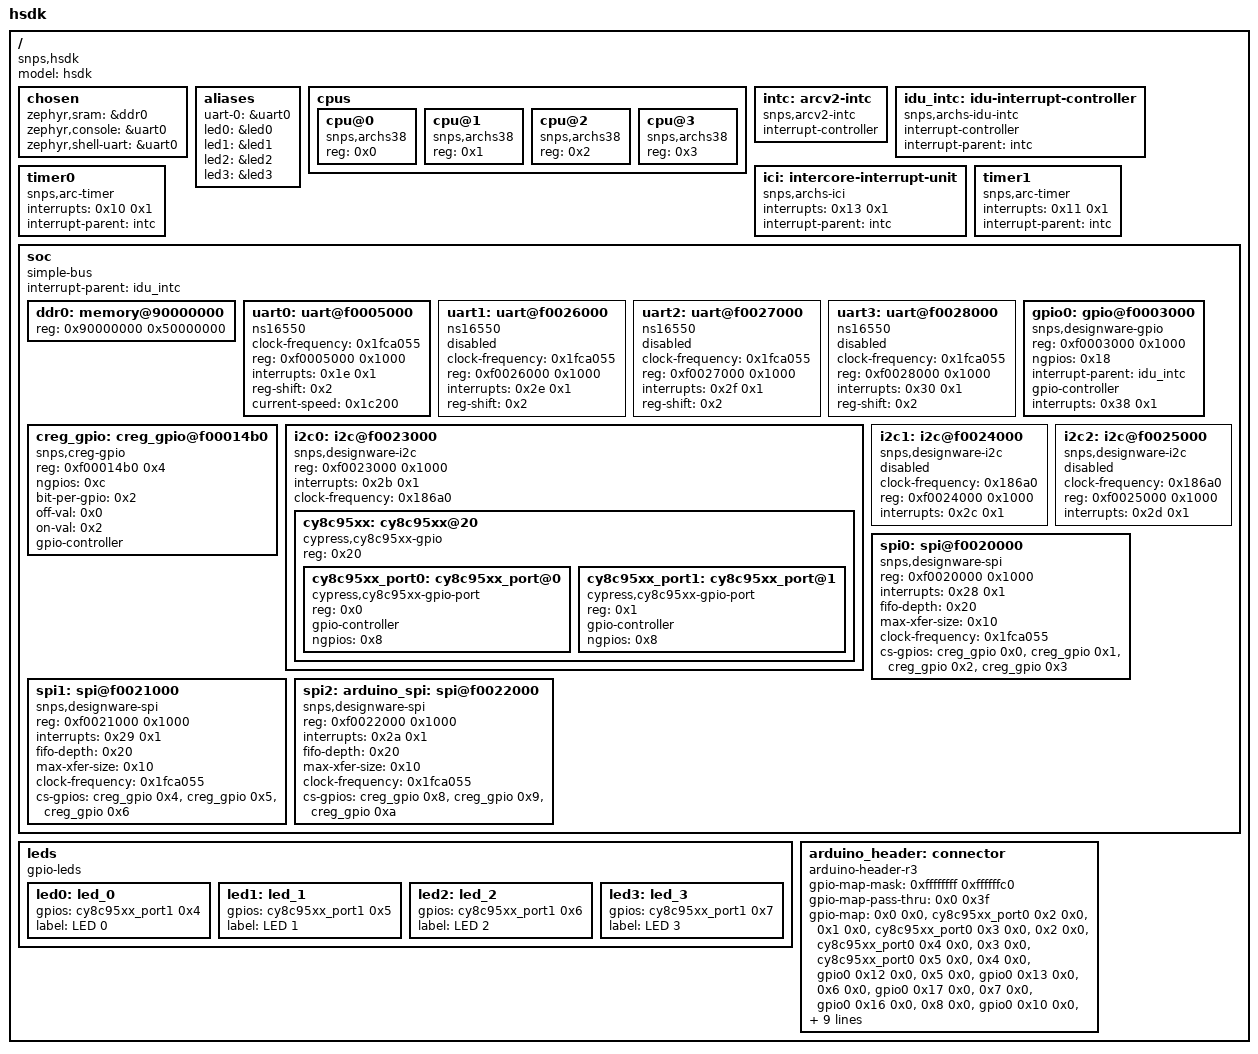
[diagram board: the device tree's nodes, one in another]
/dts-v1/;

/* node '/' defined in zephyr/dts/common/skeleton.dtsi:9 */
/ {
	#address-cells = < 0x1 >; /* in zephyr/dts/common/skeleton.dtsi:10 */
	#size-cells = < 0x1 >;    /* in zephyr/dts/common/skeleton.dtsi:11 */
	model = "hsdk";           /* in zephyr/boards/snps/hsdk/hsdk.dts:12 */
	compatible = "snps,hsdk"; /* in zephyr/boards/snps/hsdk/hsdk.dts:13 */

	/* node '/chosen' defined in zephyr/dts/common/skeleton.dtsi:13 */
	chosen {
		zephyr,sram = &ddr0;        /* in zephyr/boards/snps/hsdk/hsdk.dtsi:46 */
		zephyr,console = &uart0;    /* in zephyr/boards/snps/hsdk/hsdk.dtsi:47 */
		zephyr,shell-uart = &uart0; /* in zephyr/boards/snps/hsdk/hsdk.dtsi:48 */
	};

	/* node '/aliases' defined in zephyr/dts/common/skeleton.dtsi:15 */
	aliases {
		uart-0 = &uart0; /* in zephyr/boards/snps/hsdk/hsdk.dtsi:14 */
		led0 = &led0;    /* in zephyr/boards/snps/hsdk/hsdk.dtsi:15 */
		led1 = &led1;    /* in zephyr/boards/snps/hsdk/hsdk.dtsi:16 */
		led2 = &led2;    /* in zephyr/boards/snps/hsdk/hsdk.dtsi:17 */
		led3 = &led3;    /* in zephyr/boards/snps/hsdk/hsdk.dtsi:18 */
	};

	/* node '/cpus' defined in zephyr/dts/arc/synopsys/arc_hsdk.dtsi:13 */
	cpus {
		#address-cells = < 0x1 >; /* in zephyr/dts/arc/synopsys/arc_hsdk.dtsi:14 */
		#size-cells = < 0x0 >;    /* in zephyr/dts/arc/synopsys/arc_hsdk.dtsi:15 */

		/* node '/cpus/cpu@0' defined in zephyr/dts/arc/synopsys/arc_hsdk.dtsi:17 */
		cpu@0 {
			device_type = "cpu";         /* in zephyr/dts/arc/synopsys/arc_hsdk.dtsi:18 */
			compatible = "snps,archs38"; /* in zephyr/dts/arc/synopsys/arc_hsdk.dtsi:19 */
			reg = < 0x0 >;               /* in zephyr/dts/arc/synopsys/arc_hsdk.dtsi:20 */
		};

		/* node '/cpus/cpu@1' defined in zephyr/dts/arc/synopsys/arc_hsdk.dtsi:23 */
		cpu@1 {
			device_type = "cpu";         /* in zephyr/dts/arc/synopsys/arc_hsdk.dtsi:24 */
			compatible = "snps,archs38"; /* in zephyr/dts/arc/synopsys/arc_hsdk.dtsi:25 */
			reg = < 0x1 >;               /* in zephyr/dts/arc/synopsys/arc_hsdk.dtsi:26 */
		};

		/* node '/cpus/cpu@2' defined in zephyr/dts/arc/synopsys/arc_hsdk.dtsi:29 */
		cpu@2 {
			device_type = "cpu";         /* in zephyr/dts/arc/synopsys/arc_hsdk.dtsi:30 */
			compatible = "snps,archs38"; /* in zephyr/dts/arc/synopsys/arc_hsdk.dtsi:31 */
			reg = < 0x2 >;               /* in zephyr/dts/arc/synopsys/arc_hsdk.dtsi:32 */
		};

		/* node '/cpus/cpu@3' defined in zephyr/dts/arc/synopsys/arc_hsdk.dtsi:35 */
		cpu@3 {
			device_type = "cpu";         /* in zephyr/dts/arc/synopsys/arc_hsdk.dtsi:36 */
			compatible = "snps,archs38"; /* in zephyr/dts/arc/synopsys/arc_hsdk.dtsi:37 */
			reg = < 0x3 >;               /* in zephyr/dts/arc/synopsys/arc_hsdk.dtsi:38 */
		};
	};

	/* node '/arcv2-intc' defined in zephyr/dts/arc/synopsys/arc_hsdk.dtsi:42 */
	intc: arcv2-intc {
		compatible = "snps,arcv2-intc"; /* in zephyr/dts/arc/synopsys/arc_hsdk.dtsi:43 */
		interrupt-controller;           /* in zephyr/dts/arc/synopsys/arc_hsdk.dtsi:44 */
		#interrupt-cells = < 0x2 >;     /* in zephyr/dts/arc/synopsys/arc_hsdk.dtsi:45 */
		phandle = < 0x1 >;              /* in zephyr/dts/arc/synopsys/arc_hsdk.dtsi:52 */
	};

	/* node '/idu-interrupt-controller' defined in zephyr/dts/arc/synopsys/arc_hsdk.dtsi:48 */
	idu_intc: idu-interrupt-controller {
		compatible = "snps,archs-idu-intc"; /* in zephyr/dts/arc/synopsys/arc_hsdk.dtsi:49 */
		interrupt-controller;               /* in zephyr/dts/arc/synopsys/arc_hsdk.dtsi:50 */
		#interrupt-cells = < 0x2 >;         /* in zephyr/dts/arc/synopsys/arc_hsdk.dtsi:51 */
		interrupt-parent = < &intc >;       /* in zephyr/dts/arc/synopsys/arc_hsdk.dtsi:52 */
		phandle = < 0x2 >;                  /* in zephyr/dts/arc/synopsys/arc_hsdk.dtsi:77 */
	};

	/* node '/intercore-interrupt-unit' defined in zephyr/dts/arc/synopsys/arc_hsdk.dtsi:55 */
	ici: intercore-interrupt-unit {
		compatible = "snps,archs-ici"; /* in zephyr/dts/arc/synopsys/arc_hsdk.dtsi:56 */
		interrupts = < 0x13 0x1 >;     /* in zephyr/dts/arc/synopsys/arc_hsdk.dtsi:57 */
		interrupt-parent = < &intc >;  /* in zephyr/dts/arc/synopsys/arc_hsdk.dtsi:58 */
	};

	/* node '/timer0' defined in zephyr/dts/arc/synopsys/arc_hsdk.dtsi:61 */
	timer0: timer0 {
		compatible = "snps,arc-timer"; /* in zephyr/dts/arc/synopsys/arc_hsdk.dtsi:62 */
		interrupts = < 0x10 0x1 >;     /* in zephyr/dts/arc/synopsys/arc_hsdk.dtsi:63 */
		interrupt-parent = < &intc >;  /* in zephyr/dts/arc/synopsys/arc_hsdk.dtsi:64 */
	};

	/* node '/timer1' defined in zephyr/dts/arc/synopsys/arc_hsdk.dtsi:67 */
	timer1: timer1 {
		compatible = "snps,arc-timer"; /* in zephyr/dts/arc/synopsys/arc_hsdk.dtsi:68 */
		interrupts = < 0x11 0x1 >;     /* in zephyr/dts/arc/synopsys/arc_hsdk.dtsi:69 */
		interrupt-parent = < &intc >;  /* in zephyr/dts/arc/synopsys/arc_hsdk.dtsi:70 */
	};

	/* node '/soc' defined in zephyr/dts/arc/synopsys/arc_hsdk.dtsi:73 */
	soc {
		#address-cells = < 0x1 >;         /* in zephyr/dts/arc/synopsys/arc_hsdk.dtsi:74 */
		#size-cells = < 0x1 >;            /* in zephyr/dts/arc/synopsys/arc_hsdk.dtsi:75 */
		compatible = "simple-bus";        /* in zephyr/dts/arc/synopsys/arc_hsdk.dtsi:76 */
		interrupt-parent = < &idu_intc >; /* in zephyr/dts/arc/synopsys/arc_hsdk.dtsi:77 */
		ranges;                           /* in zephyr/dts/arc/synopsys/arc_hsdk.dtsi:78 */

		/* node '/soc/memory@90000000' defined in zephyr/dts/arc/synopsys/arc_hsdk.dtsi:80 */
		ddr0: memory@90000000 {
			device_type = "memory";          /* in zephyr/dts/arc/synopsys/arc_hsdk.dtsi:81 */
			reg = < 0x90000000 0x50000000 >; /* in zephyr/dts/arc/synopsys/arc_hsdk.dtsi:82 */
		};

		/* node '/soc/uart@f0005000' defined in zephyr/dts/arc/synopsys/arc_hsdk.dtsi:85 */
		uart0: uart@f0005000 {
			compatible = "ns16550";          /* in zephyr/dts/arc/synopsys/arc_hsdk.dtsi:86 */
			clock-frequency = < 0x1fca055 >; /* in zephyr/dts/arc/synopsys/arc_hsdk.dtsi:87 */
			reg = < 0xf0005000 0x1000 >;     /* in zephyr/dts/arc/synopsys/arc_hsdk.dtsi:88 */
			interrupts = < 0x1e 0x1 >;       /* in zephyr/dts/arc/synopsys/arc_hsdk.dtsi:89 */
			reg-shift = < 0x2 >;             /* in zephyr/dts/arc/synopsys/arc_hsdk.dtsi:90 */
			status = "okay";                 /* in zephyr/boards/snps/hsdk/hsdk.dtsi:84 */
			current-speed = < 0x1c200 >;     /* in zephyr/boards/snps/hsdk/hsdk.dtsi:85 */
		};

		/* node '/soc/uart@f0026000' defined in zephyr/dts/arc/synopsys/arc_hsdk.dtsi:93 */
		uart1: uart@f0026000 {
			compatible = "ns16550";          /* in zephyr/dts/arc/synopsys/arc_hsdk.dtsi:94 */
			clock-frequency = < 0x1fca055 >; /* in zephyr/dts/arc/synopsys/arc_hsdk.dtsi:95 */
			reg = < 0xf0026000 0x1000 >;     /* in zephyr/dts/arc/synopsys/arc_hsdk.dtsi:96 */
			interrupts = < 0x2e 0x1 >;       /* in zephyr/dts/arc/synopsys/arc_hsdk.dtsi:97 */
			reg-shift = < 0x2 >;             /* in zephyr/dts/arc/synopsys/arc_hsdk.dtsi:98 */
			status = "disabled";             /* in zephyr/dts/arc/synopsys/arc_hsdk.dtsi:99 */
		};

		/* node '/soc/uart@f0027000' defined in zephyr/dts/arc/synopsys/arc_hsdk.dtsi:102 */
		uart2: uart@f0027000 {
			compatible = "ns16550";          /* in zephyr/dts/arc/synopsys/arc_hsdk.dtsi:103 */
			clock-frequency = < 0x1fca055 >; /* in zephyr/dts/arc/synopsys/arc_hsdk.dtsi:104 */
			reg = < 0xf0027000 0x1000 >;     /* in zephyr/dts/arc/synopsys/arc_hsdk.dtsi:105 */
			interrupts = < 0x2f 0x1 >;       /* in zephyr/dts/arc/synopsys/arc_hsdk.dtsi:106 */
			reg-shift = < 0x2 >;             /* in zephyr/dts/arc/synopsys/arc_hsdk.dtsi:107 */
			status = "disabled";             /* in zephyr/dts/arc/synopsys/arc_hsdk.dtsi:108 */
		};

		/* node '/soc/uart@f0028000' defined in zephyr/dts/arc/synopsys/arc_hsdk.dtsi:111 */
		uart3: uart@f0028000 {
			compatible = "ns16550";          /* in zephyr/dts/arc/synopsys/arc_hsdk.dtsi:112 */
			clock-frequency = < 0x1fca055 >; /* in zephyr/dts/arc/synopsys/arc_hsdk.dtsi:113 */
			reg = < 0xf0028000 0x1000 >;     /* in zephyr/dts/arc/synopsys/arc_hsdk.dtsi:114 */
			interrupts = < 0x30 0x1 >;       /* in zephyr/dts/arc/synopsys/arc_hsdk.dtsi:115 */
			reg-shift = < 0x2 >;             /* in zephyr/dts/arc/synopsys/arc_hsdk.dtsi:116 */
			status = "disabled";             /* in zephyr/dts/arc/synopsys/arc_hsdk.dtsi:117 */
		};

		/* node '/soc/gpio@f0003000' defined in zephyr/dts/arc/synopsys/arc_hsdk.dtsi:120 */
		gpio0: gpio@f0003000 {
			compatible = "snps,designware-gpio"; /* in zephyr/dts/arc/synopsys/arc_hsdk.dtsi:121 */
			reg = < 0xf0003000 0x1000 >;         /* in zephyr/dts/arc/synopsys/arc_hsdk.dtsi:122 */
			ngpios = < 0x18 >;                   /* in zephyr/dts/arc/synopsys/arc_hsdk.dtsi:123 */
			interrupt-parent = < &idu_intc >;    /* in zephyr/dts/arc/synopsys/arc_hsdk.dtsi:124 */
			gpio-controller;                     /* in zephyr/dts/arc/synopsys/arc_hsdk.dtsi:126 */
			#gpio-cells = < 0x2 >;               /* in zephyr/dts/arc/synopsys/arc_hsdk.dtsi:127 */
			status = "okay";                     /* in zephyr/boards/snps/hsdk/hsdk.dtsi:89 */
			interrupts = < 0x38 0x1 >;           /* in zephyr/boards/snps/hsdk/hsdk.dtsi:90 */
			phandle = < 0x6 >;                   /* in zephyr/boards/snps/hsdk/hsdk.dtsi:56 */
		};

		/* node '/soc/creg_gpio@f00014b0' defined in zephyr/dts/arc/synopsys/arc_hsdk.dtsi:132 */
		creg_gpio: creg_gpio@f00014b0 {
			compatible = "snps,creg-gpio"; /* in zephyr/dts/arc/synopsys/arc_hsdk.dtsi:133 */
			reg = < 0xf00014b0 0x4 >;      /* in zephyr/dts/arc/synopsys/arc_hsdk.dtsi:134 */
			ngpios = < 0xc >;              /* in zephyr/dts/arc/synopsys/arc_hsdk.dtsi:135 */
			bit-per-gpio = < 0x2 >;        /* in zephyr/dts/arc/synopsys/arc_hsdk.dtsi:136 */
			off-val = < 0x0 >;             /* in zephyr/dts/arc/synopsys/arc_hsdk.dtsi:137 */
			on-val = < 0x2 >;              /* in zephyr/dts/arc/synopsys/arc_hsdk.dtsi:138 */
			gpio-controller;               /* in zephyr/dts/arc/synopsys/arc_hsdk.dtsi:140 */
			#gpio-cells = < 0x2 >;         /* in zephyr/dts/arc/synopsys/arc_hsdk.dtsi:141 */
			status = "okay";               /* in zephyr/boards/snps/hsdk/hsdk.dtsi:94 */
			phandle = < 0x3 >;             /* in zephyr/boards/snps/hsdk/hsdk.dtsi:100 */
		};

		/* node '/soc/i2c@f0023000' defined in zephyr/dts/arc/synopsys/arc_hsdk.dtsi:146 */
		i2c0: i2c@f0023000 {
			compatible = "snps,designware-i2c"; /* in zephyr/dts/arc/synopsys/arc_hsdk.dtsi:147 */
			#address-cells = < 0x1 >;           /* in zephyr/dts/arc/synopsys/arc_hsdk.dtsi:149 */
			#size-cells = < 0x0 >;              /* in zephyr/dts/arc/synopsys/arc_hsdk.dtsi:150 */
			reg = < 0xf0023000 0x1000 >;        /* in zephyr/dts/arc/synopsys/arc_hsdk.dtsi:151 */
			interrupts = < 0x2b 0x1 >;          /* in zephyr/dts/arc/synopsys/arc_hsdk.dtsi:152 */
			status = "okay";                    /* in zephyr/boards/snps/hsdk/hsdk.dtsi:123 */
			clock-frequency = < 0x186a0 >;      /* in zephyr/boards/snps/hsdk/hsdk.dtsi:124 */

			/* node '/soc/i2c@f0023000/cy8c95xx@20' defined in zephyr/boards/snps/hsdk/hsdk.dtsi:126 */
			cy8c95xx: cy8c95xx@20 {
				compatible = "cypress,cy8c95xx-gpio"; /* in zephyr/boards/snps/hsdk/hsdk.dtsi:127 */
				reg = < 0x20 >;                       /* in zephyr/boards/snps/hsdk/hsdk.dtsi:128 */
				ranges;                               /* in zephyr/boards/snps/hsdk/hsdk.dtsi:129 */
				#address-cells = < 0x1 >;             /* in zephyr/boards/snps/hsdk/hsdk.dtsi:130 */
				#size-cells = < 0x0 >;                /* in zephyr/boards/snps/hsdk/hsdk.dtsi:131 */

				/* node '/soc/i2c@f0023000/cy8c95xx@20/cy8c95xx_port@0' defined in zephyr/boards/snps/hsdk/hsdk.dtsi:133 */
				cy8c95xx_port0: cy8c95xx_port@0 {
					compatible = "cypress,cy8c95xx-gpio-port"; /* in zephyr/boards/snps/hsdk/hsdk.dtsi:134 */
					reg = < 0x0 >;                             /* in zephyr/boards/snps/hsdk/hsdk.dtsi:135 */
					gpio-controller;                           /* in zephyr/boards/snps/hsdk/hsdk.dtsi:136 */
					#gpio-cells = < 0x2 >;                     /* in zephyr/boards/snps/hsdk/hsdk.dtsi:137 */
					ngpios = < 0x8 >;                          /* in zephyr/boards/snps/hsdk/hsdk.dtsi:138 */
					status = "okay";                           /* in zephyr/boards/snps/hsdk/hsdk.dtsi:139 */
					phandle = < 0x5 >;                         /* in zephyr/boards/snps/hsdk/hsdk.dtsi:56 */
				};

				/* node '/soc/i2c@f0023000/cy8c95xx@20/cy8c95xx_port@1' defined in zephyr/boards/snps/hsdk/hsdk.dtsi:142 */
				cy8c95xx_port1: cy8c95xx_port@1 {
					compatible = "cypress,cy8c95xx-gpio-port"; /* in zephyr/boards/snps/hsdk/hsdk.dtsi:143 */
					reg = < 0x1 >;                             /* in zephyr/boards/snps/hsdk/hsdk.dtsi:144 */
					gpio-controller;                           /* in zephyr/boards/snps/hsdk/hsdk.dtsi:145 */
					#gpio-cells = < 0x2 >;                     /* in zephyr/boards/snps/hsdk/hsdk.dtsi:146 */
					ngpios = < 0x8 >;                          /* in zephyr/boards/snps/hsdk/hsdk.dtsi:147 */
					status = "okay";                           /* in zephyr/boards/snps/hsdk/hsdk.dtsi:148 */
					phandle = < 0x4 >;                         /* in zephyr/boards/snps/hsdk/hsdk.dtsi:25 */
				};
			};
		};

		/* node '/soc/i2c@f0024000' defined in zephyr/dts/arc/synopsys/arc_hsdk.dtsi:157 */
		i2c1: i2c@f0024000 {
			compatible = "snps,designware-i2c"; /* in zephyr/dts/arc/synopsys/arc_hsdk.dtsi:158 */
			clock-frequency = < 0x186a0 >;      /* in zephyr/dts/arc/synopsys/arc_hsdk.dtsi:159 */
			#address-cells = < 0x1 >;           /* in zephyr/dts/arc/synopsys/arc_hsdk.dtsi:160 */
			#size-cells = < 0x0 >;              /* in zephyr/dts/arc/synopsys/arc_hsdk.dtsi:161 */
			reg = < 0xf0024000 0x1000 >;        /* in zephyr/dts/arc/synopsys/arc_hsdk.dtsi:162 */
			interrupts = < 0x2c 0x1 >;          /* in zephyr/dts/arc/synopsys/arc_hsdk.dtsi:163 */
			status = "disabled";                /* in zephyr/dts/arc/synopsys/arc_hsdk.dtsi:165 */
		};

		/* node '/soc/i2c@f0025000' defined in zephyr/dts/arc/synopsys/arc_hsdk.dtsi:168 */
		i2c2: i2c@f0025000 {
			compatible = "snps,designware-i2c"; /* in zephyr/dts/arc/synopsys/arc_hsdk.dtsi:169 */
			clock-frequency = < 0x186a0 >;      /* in zephyr/dts/arc/synopsys/arc_hsdk.dtsi:170 */
			#address-cells = < 0x1 >;           /* in zephyr/dts/arc/synopsys/arc_hsdk.dtsi:171 */
			#size-cells = < 0x0 >;              /* in zephyr/dts/arc/synopsys/arc_hsdk.dtsi:172 */
			reg = < 0xf0025000 0x1000 >;        /* in zephyr/dts/arc/synopsys/arc_hsdk.dtsi:173 */
			interrupts = < 0x2d 0x1 >;          /* in zephyr/dts/arc/synopsys/arc_hsdk.dtsi:174 */
			status = "disabled";                /* in zephyr/dts/arc/synopsys/arc_hsdk.dtsi:176 */
		};

		/* node '/soc/spi@f0020000' defined in zephyr/dts/arc/synopsys/arc_hsdk.dtsi:179 */
		spi0: spi@f0020000 {
			compatible = "snps,designware-spi"; /* in zephyr/dts/arc/synopsys/arc_hsdk.dtsi:180 */
			#address-cells = < 0x1 >;           /* in zephyr/dts/arc/synopsys/arc_hsdk.dtsi:181 */
			#size-cells = < 0x0 >;              /* in zephyr/dts/arc/synopsys/arc_hsdk.dtsi:182 */
			reg = < 0xf0020000 0x1000 >;        /* in zephyr/dts/arc/synopsys/arc_hsdk.dtsi:183 */
			interrupts = < 0x28 0x1 >;          /* in zephyr/dts/arc/synopsys/arc_hsdk.dtsi:184 */
			fifo-depth = < 0x20 >;              /* in zephyr/dts/arc/synopsys/arc_hsdk.dtsi:185 */
			max-xfer-size = < 0x10 >;           /* in zephyr/dts/arc/synopsys/arc_hsdk.dtsi:186 */
			status = "okay";                    /* in zephyr/boards/snps/hsdk/hsdk.dtsi:98 */
			clock-frequency = < 0x1fca055 >;    /* in zephyr/boards/snps/hsdk/hsdk.dtsi:99 */
			cs-gpios = < &creg_gpio 0x0 0x0 >,
			           < &creg_gpio 0x1 0x0 >,
			           < &creg_gpio 0x2 0x0 >,
			           < &creg_gpio 0x3 0x0 >;  /* in zephyr/boards/snps/hsdk/hsdk.dtsi:100 */
		};

		/* node '/soc/spi@f0021000' defined in zephyr/dts/arc/synopsys/arc_hsdk.dtsi:190 */
		spi1: spi@f0021000 {
			compatible = "snps,designware-spi"; /* in zephyr/dts/arc/synopsys/arc_hsdk.dtsi:191 */
			#address-cells = < 0x1 >;           /* in zephyr/dts/arc/synopsys/arc_hsdk.dtsi:192 */
			#size-cells = < 0x0 >;              /* in zephyr/dts/arc/synopsys/arc_hsdk.dtsi:193 */
			reg = < 0xf0021000 0x1000 >;        /* in zephyr/dts/arc/synopsys/arc_hsdk.dtsi:194 */
			interrupts = < 0x29 0x1 >;          /* in zephyr/dts/arc/synopsys/arc_hsdk.dtsi:195 */
			fifo-depth = < 0x20 >;              /* in zephyr/dts/arc/synopsys/arc_hsdk.dtsi:196 */
			max-xfer-size = < 0x10 >;           /* in zephyr/dts/arc/synopsys/arc_hsdk.dtsi:197 */
			status = "okay";                    /* in zephyr/boards/snps/hsdk/hsdk.dtsi:107 */
			clock-frequency = < 0x1fca055 >;    /* in zephyr/boards/snps/hsdk/hsdk.dtsi:108 */
			cs-gpios = < &creg_gpio 0x4 0x0 >,
			           < &creg_gpio 0x5 0x0 >,
			           < &creg_gpio 0x6 0x0 >;  /* in zephyr/boards/snps/hsdk/hsdk.dtsi:109 */
		};

		/* node '/soc/spi@f0022000' defined in zephyr/dts/arc/synopsys/arc_hsdk.dtsi:201 */
		spi2: arduino_spi: spi@f0022000 {
			compatible = "snps,designware-spi"; /* in zephyr/dts/arc/synopsys/arc_hsdk.dtsi:202 */
			#address-cells = < 0x1 >;           /* in zephyr/dts/arc/synopsys/arc_hsdk.dtsi:203 */
			#size-cells = < 0x0 >;              /* in zephyr/dts/arc/synopsys/arc_hsdk.dtsi:204 */
			reg = < 0xf0022000 0x1000 >;        /* in zephyr/dts/arc/synopsys/arc_hsdk.dtsi:205 */
			interrupts = < 0x2a 0x1 >;          /* in zephyr/dts/arc/synopsys/arc_hsdk.dtsi:206 */
			fifo-depth = < 0x20 >;              /* in zephyr/dts/arc/synopsys/arc_hsdk.dtsi:207 */
			max-xfer-size = < 0x10 >;           /* in zephyr/dts/arc/synopsys/arc_hsdk.dtsi:208 */
			status = "okay";                    /* in zephyr/boards/snps/hsdk/hsdk.dtsi:115 */
			clock-frequency = < 0x1fca055 >;    /* in zephyr/boards/snps/hsdk/hsdk.dtsi:116 */
			cs-gpios = < &creg_gpio 0x8 0x0 >,
			           < &creg_gpio 0x9 0x0 >,
			           < &creg_gpio 0xa 0x0 >;  /* in zephyr/boards/snps/hsdk/hsdk.dtsi:117 */
		};
	};

	/* node '/leds' defined in zephyr/boards/snps/hsdk/hsdk.dtsi:21 */
	leds {
		compatible = "gpio-leds"; /* in zephyr/boards/snps/hsdk/hsdk.dtsi:22 */

		/* node '/leds/led_0' defined in zephyr/boards/snps/hsdk/hsdk.dtsi:24 */
		led0: led_0 {
			gpios = < &cy8c95xx_port1 0x4 0x0 >; /* in zephyr/boards/snps/hsdk/hsdk.dtsi:25 */
			label = "LED 0";                     /* in zephyr/boards/snps/hsdk/hsdk.dtsi:26 */
		};

		/* node '/leds/led_1' defined in zephyr/boards/snps/hsdk/hsdk.dtsi:29 */
		led1: led_1 {
			gpios = < &cy8c95xx_port1 0x5 0x0 >; /* in zephyr/boards/snps/hsdk/hsdk.dtsi:30 */
			label = "LED 1";                     /* in zephyr/boards/snps/hsdk/hsdk.dtsi:31 */
		};

		/* node '/leds/led_2' defined in zephyr/boards/snps/hsdk/hsdk.dtsi:34 */
		led2: led_2 {
			gpios = < &cy8c95xx_port1 0x6 0x0 >; /* in zephyr/boards/snps/hsdk/hsdk.dtsi:35 */
			label = "LED 2";                     /* in zephyr/boards/snps/hsdk/hsdk.dtsi:36 */
		};

		/* node '/leds/led_3' defined in zephyr/boards/snps/hsdk/hsdk.dtsi:39 */
		led3: led_3 {
			gpios = < &cy8c95xx_port1 0x7 0x0 >; /* in zephyr/boards/snps/hsdk/hsdk.dtsi:40 */
			label = "LED 3";                     /* in zephyr/boards/snps/hsdk/hsdk.dtsi:41 */
		};
	};

	/* node '/connector' defined in zephyr/boards/snps/hsdk/hsdk.dtsi:51 */
	arduino_header: connector {
		compatible = "arduino-header-r3";               /* in zephyr/boards/snps/hsdk/hsdk.dtsi:52 */
		#gpio-cells = < 0x2 >;                          /* in zephyr/boards/snps/hsdk/hsdk.dtsi:53 */
		gpio-map-mask = < 0xffffffff 0xffffffc0 >;      /* in zephyr/boards/snps/hsdk/hsdk.dtsi:54 */
		gpio-map-pass-thru = < 0x0 0x3f >;              /* in zephyr/boards/snps/hsdk/hsdk.dtsi:55 */
		gpio-map = < 0x0 0x0 &cy8c95xx_port0 0x2 0x0 >,
		           < 0x1 0x0 &cy8c95xx_port0 0x3 0x0 >,
		           < 0x2 0x0 &cy8c95xx_port0 0x4 0x0 >,
		           < 0x3 0x0 &cy8c95xx_port0 0x5 0x0 >,
		           < 0x4 0x0 &gpio0 0x12 0x0 >,
		           < 0x5 0x0 &gpio0 0x13 0x0 >,
		           < 0x6 0x0 &gpio0 0x17 0x0 >,
		           < 0x7 0x0 &gpio0 0x16 0x0 >,
		           < 0x8 0x0 &gpio0 0x10 0x0 >,
		           < 0x9 0x0 &gpio0 0x11 0x0 >,
		           < 0xa 0x0 &gpio0 0xb 0x0 >,
		           < 0xb 0x0 &gpio0 0x9 0x0 >,
		           < 0xc 0x0 &gpio0 0x15 0x0 >,
		           < 0xd 0x0 &gpio0 0x14 0x0 >,
		           < 0xe 0x0 &gpio0 0xa 0x0 >,
		           < 0xf 0x0 &gpio0 0x8 0x0 >,
		           < 0x10 0x0 &gpio0 0xc 0x0 >,
		           < 0x11 0x0 &gpio0 0xd 0x0 >,
		           < 0x12 0x0 &gpio0 0xe 0x0 >,
		           < 0x13 0x0 &gpio0 0xf 0x0 >,
		           < 0x14 0x0 &gpio0 0x12 0x0 >,
		           < 0x15 0x0 &gpio0 0x13 0x0 >;        /* in zephyr/boards/snps/hsdk/hsdk.dtsi:56 */
	};
};
